VERSION ""

NS_ :

BS_:

BU_: EngineControl

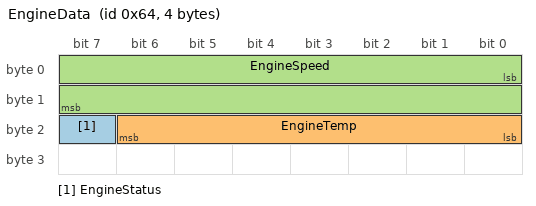
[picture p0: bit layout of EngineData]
BO_ 100 EngineData: 4 EngineControl
 SG_ EngineStatus : 23|1@1+ (1,0) [0|1] "" Vector__XXX
 SG_ EngineTemp : 16|7@1+ (1,0) [0|100] "degC" Vector__XXX
 SG_ EngineSpeed : 0|16@1+ (1,0) [0|5000] "RPM" Vector__XXX
